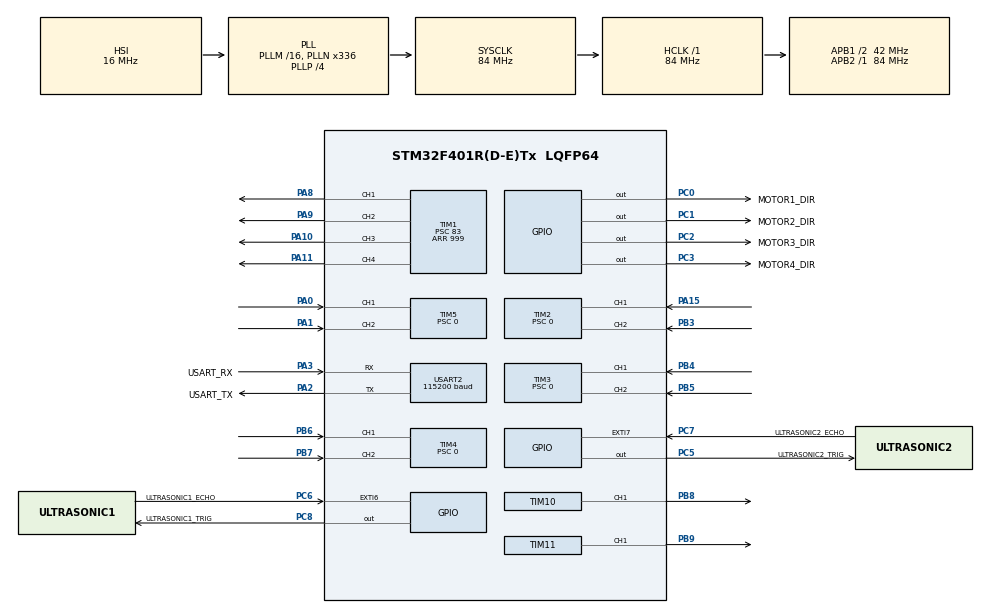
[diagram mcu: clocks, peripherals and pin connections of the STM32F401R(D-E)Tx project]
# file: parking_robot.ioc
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Mcu.Family=STM32F4
Mcu.Name=STM32F401R(D-E)Tx
Mcu.Package=LQFP64
NVIC.EXTI9_5_IRQn=true\:0\:0\:false\:false\:true\:true\:true\:true
NVIC.PriorityGroup=NVIC_PRIORITYGROUP_4
NVIC.USART2_IRQn=true\:0\:0\:false\:false\:true\:true\:true\:true
PA0-WKUP.GPIO_PuPd=GPIO_PULLUP
PA0-WKUP.Signal=S_TIM5_CH1
PA1.GPIO_PuPd=GPIO_PULLUP
PA1.Signal=S_TIM5_CH2
PA10.Signal=S_TIM1_CH3
PA11.Signal=S_TIM1_CH4
PA13.GPIO_Label=TMS
PA13.Mode=Serial_Wire
PA13.Signal=SYS_JTMS-SWDIO
PA14.GPIO_Label=TCK
PA14.Mode=Serial_Wire
PA14.Signal=SYS_JTCK-SWCLK
PA15.GPIO_PuPd=GPIO_PULLUP
PA15.Signal=S_TIM2_CH1_ETR
PA2.GPIO_Label=USART_TX
PA2.GPIO_Mode=GPIO_MODE_AF_PP
PA2.GPIO_PuPd=GPIO_NOPULL
PA2.GPIO_Speed=GPIO_SPEED_FREQ_LOW
PA2.Mode=Asynchronous
PA2.Signal=USART2_TX
PA3.GPIO_Label=USART_RX
PA3.GPIO_Mode=GPIO_MODE_AF_PP
PA3.GPIO_PuPd=GPIO_NOPULL
PA3.GPIO_Speed=GPIO_SPEED_FREQ_LOW
PA3.Mode=Asynchronous
PA3.Signal=USART2_RX
PA8.Signal=S_TIM1_CH1
PA9.Signal=S_TIM1_CH2
PB3.GPIO_PuPd=GPIO_PULLUP
PB3.Signal=S_TIM2_CH2
PB4.GPIO_PuPd=GPIO_PULLUP
PB4.Signal=S_TIM3_CH1
PB5.GPIO_PuPd=GPIO_PULLUP
PB5.Signal=S_TIM3_CH2
PB6.GPIO_PuPd=GPIO_PULLUP
PB6.Signal=S_TIM4_CH1
PB7.GPIO_PuPd=GPIO_PULLUP
PB7.Signal=S_TIM4_CH2
PB8.Signal=S_TIM10_CH1
PB9.Signal=S_TIM11_CH1
PC0.GPIO_Label=MOTOR1_DIR
PC0.GPIO_ModeDefaultOutputPP=GPIO_MODE_OUTPUT_PP
PC0.GPIO_PuPd=GPIO_NOPULL
PC0.GPIO_Speed=GPIO_SPEED_FREQ_LOW
PC0.PinState=GPIO_PIN_RESET
PC0.Signal=GPIO_Output
PC1.GPIO_Label=MOTOR2_DIR
PC1.GPIO_ModeDefaultOutputPP=GPIO_MODE_OUTPUT_PP
PC1.GPIO_PuPd=GPIO_NOPULL
PC1.GPIO_Speed=GPIO_SPEED_FREQ_LOW
PC1.PinState=GPIO_PIN_RESET
PC1.Signal=GPIO_Output
PC2.GPIO_Label=MOTOR3_DIR
PC2.GPIO_ModeDefaultOutputPP=GPIO_MODE_OUTPUT_PP
PC2.GPIO_PuPd=GPIO_NOPULL
PC2.GPIO_Speed=GPIO_SPEED_FREQ_LOW
PC2.PinState=GPIO_PIN_RESET
PC2.Signal=GPIO_Output
PC3.GPIO_Label=MOTOR4_DIR
PC3.GPIO_ModeDefaultOutputPP=GPIO_MODE_OUTPUT_PP
PC3.GPIO_PuPd=GPIO_NOPULL
PC3.GPIO_Speed=GPIO_SPEED_FREQ_LOW
PC3.PinState=GPIO_PIN_RESET
PC3.Signal=GPIO_Output
PC5.GPIO_Label=ULTRASONIC2_TRIG
PC5.GPIO_ModeDefaultOutputPP=GPIO_MODE_OUTPUT_PP
PC5.GPIO_PuPd=GPIO_NOPULL
PC5.GPIO_Speed=GPIO_SPEED_FREQ_LOW
PC5.PinState=GPIO_PIN_RESET
PC5.Signal=GPIO_Output
PC6.GPIO_Label=ULTRASONIC1_ECHO
PC6.GPIO_ModeDefaultEXTI=GPIO_MODE_IT_RISING_FALLING
PC6.GPIO_PuPd=GPIO_NOPULL
PC6.Signal=GPXTI6
PC7.GPIO_Label=ULTRASONIC2_ECHO
PC7.GPIO_ModeDefaultEXTI=GPIO_MODE_IT_RISING_FALLING
PC7.GPIO_PuPd=GPIO_NOPULL
PC7.Signal=GPXTI7
PC8.GPIO_Label=ULTRASONIC1_TRIG
PC8.GPIO_ModeDefaultOutputPP=GPIO_MODE_OUTPUT_PP
PC8.GPIO_PuPd=GPIO_NOPULL
PC8.GPIO_Speed=GPIO_SPEED_FREQ_LOW
PC8.PinState=GPIO_PIN_RESET
PC8.Signal=GPIO_Output
PH0\ -\ OSC_IN.Mode=HSE-External-Clock-Source
PH0\ -\ OSC_IN.Signal=RCC_OSC_IN
PH1\ -\ OSC_OUT.Mode=HSE-External-Clock-Source
PH1\ -\ OSC_OUT.Signal=RCC_OSC_OUT
ProjectManager.HeapSize=0x200
ProjectManager.StackSize=0x400
ProjectManager.TargetToolchain=STM32CubeIDE
RCC.48MHZClocksFreq_Value=48000000
RCC.AHBFreq_Value=84000000
RCC.APB1CLKDivider=RCC_HCLK_DIV2
RCC.APB1Freq_Value=42000000
RCC.APB1TimFreq_Value=84000000
RCC.APB2Freq_Value=84000000
RCC.APB2TimFreq_Value=84000000
RCC.CortexFreq_Value=84000000
RCC.HCLKFreq_Value=84000000
RCC.HSE_VALUE=8000000
RCC.HSI_VALUE=16000000
RCC.LSE_VALUE=32768
RCC.PLLN=336
RCC.PLLP=RCC_PLLP_DIV4
RCC.PLLQ=7
RCC.SYSCLKFreq_VALUE=84000000
RCC.SYSCLKSource=RCC_SYSCLKSOURCE_PLLCLK
RCC.VCOOutputFreq_Value=336000000
SH.S_TIM10_CH1.0=TIM10_CH1,PWM Generation1 CH1
SH.S_TIM11_CH1.0=TIM11_CH1,PWM Generation1 CH1
SH.S_TIM1_CH1.0=TIM1_CH1,PWM Generation1 CH1
SH.S_TIM1_CH2.0=TIM1_CH2,PWM Generation2 CH2
SH.S_TIM1_CH3.0=TIM1_CH3,PWM Generation3 CH3
SH.S_TIM1_CH4.0=TIM1_CH4,PWM Generation4 CH4
SH.S_TIM2_CH1_ETR.0=TIM2_CH1,Encoder_Interface
SH.S_TIM2_CH2.0=TIM2_CH2,Encoder_Interface
SH.S_TIM3_CH1.0=TIM3_CH1,Encoder_Interface
SH.S_TIM3_CH2.0=TIM3_CH2,Encoder_Interface
SH.S_TIM4_CH1.0=TIM4_CH1,Encoder_Interface
SH.S_TIM4_CH2.0=TIM4_CH2,Encoder_Interface
SH.S_TIM5_CH1.0=TIM5_CH1,Encoder_Interface
SH.S_TIM5_CH2.0=TIM5_CH2,Encoder_Interface
TIM1.Channel-PWM\ Generation1\ CH1=TIM_CHANNEL_1
TIM1.Channel-PWM\ Generation2\ CH2=TIM_CHANNEL_2
TIM1.Channel-PWM\ Generation3\ CH3=TIM_CHANNEL_3
TIM1.Channel-PWM\ Generation4\ CH4=TIM_CHANNEL_4
TIM1.Period=999
TIM1.Prescaler=83
TIM10.Channel=TIM_CHANNEL_1
TIM10.Period=19999
TIM10.Prescaler=83
TIM11.Channel=TIM_CHANNEL_1
TIM11.Period=19999
TIM11.Prescaler=83
TIM2.EncoderMode=TIM_ENCODERMODE_TI12
TIM2.IC1Filter=15
TIM2.IC2Filter=15
TIM2.Period=4294967295
TIM2.Prescaler=0
TIM3.EncoderMode=TIM_ENCODERMODE_TI12
TIM3.IC1Filter=15
TIM3.IC2Filter=15
TIM3.Period=65535
TIM3.Prescaler=0
TIM4.EncoderMode=TIM_ENCODERMODE_TI12
TIM4.IC1Filter=15
TIM4.IC2Filter=15
TIM4.Period=65535
TIM4.Prescaler=0
TIM5.EncoderMode=TIM_ENCODERMODE_TI12
TIM5.IC1Filter=15
TIM5.IC2Filter=15
TIM5.Period=4294967295
TIM5.Prescaler=0
TIM9.Period=65535
TIM9.Prescaler=83
USART2.BaudRate=115200
USART2.Parity=PARITY_NONE
USART2.StopBits=STOPBITS_1
USART2.VirtualMode=VM_ASYNC
USART2.WordLength=WORDLENGTH_8B
VP_TIM10_VS_ClockSourceINT.Mode=Enable_Timer
VP_TIM11_VS_ClockSourceINT.Mode=Enable_Timer
VP_TIM1_VS_ClockSourceINT.Mode=Internal
VP_TIM9_VS_ClockSourceINT.Mode=Internal
board=NUCLEO-F401RE

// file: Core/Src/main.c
/* USER CODE BEGIN Header */
/**
  ******************************************************************************
  * @file           : main.c
  * @brief          : Main program body
  ******************************************************************************
  * @attention
  *
  * Copyright (c) 2026 STMicroelectronics.
  * All rights reserved.
  *
  * This software is licensed under terms that can be found in the LICENSE file
  * in the root directory of this software component.
  * If no LICENSE file comes with this software, it is provided AS-IS.
  *
  ******************************************************************************
  */
/* USER CODE END Header */
#include "main.h"

/* USER CODE BEGIN Includes */
#include "parking_robot_firmware.h"
/* USER CODE END Includes */

TIM_HandleTypeDef htim1;
TIM_HandleTypeDef htim2;
TIM_HandleTypeDef htim3;
TIM_HandleTypeDef htim4;
TIM_HandleTypeDef htim5;
TIM_HandleTypeDef htim9;
TIM_HandleTypeDef htim10;
TIM_HandleTypeDef htim11;

UART_HandleTypeDef huart2;

void SystemClock_Config(void);
static void MX_GPIO_Init(void);
static void MX_TIM1_Init(void);
static void MX_TIM2_Init(void);
static void MX_TIM3_Init(void);
static void MX_TIM4_Init(void);
static void MX_TIM5_Init(void);
static void MX_TIM9_Init(void);
static void MX_TIM10_Init(void);
static void MX_TIM11_Init(void);
static void MX_USART2_UART_Init(void);

int main(void)
{

  /* MCU Configuration--------------------------------------------------------*/

  /* Reset of all peripherals, Initializes the Flash interface and the Systick. */
  HAL_Init();

  /* Configure the system clock */
  SystemClock_Config();

  /* Initialize all configured peripherals */
  MX_GPIO_Init();
  MX_TIM1_Init();
  MX_TIM2_Init();
  MX_TIM3_Init();
  MX_TIM4_Init();
  MX_TIM5_Init();
  MX_TIM9_Init();
  MX_TIM10_Init();
  MX_TIM11_Init();
  MX_USART2_UART_Init();
  /* USER CODE BEGIN 2 */
  Robot_Init();
  /* USER CODE END 2 */

  /* Infinite loop */
  while (1)
  {

    /* USER CODE BEGIN 3 */
    Robot_MainLoop();
  }
  /* USER CODE END 3 */
}

void SystemClock_Config(void)
{
  RCC_OscInitTypeDef RCC_OscInitStruct = {0};
  RCC_ClkInitTypeDef RCC_ClkInitStruct = {0};

  /** Configure the main internal regulator output voltage
  */
  __HAL_RCC_PWR_CLK_ENABLE();
  __HAL_PWR_VOLTAGESCALING_CONFIG(PWR_REGULATOR_VOLTAGE_SCALE2);

  /** Initializes the RCC Oscillators according to the specified parameters
  * in the RCC_OscInitTypeDef structure.
  */
  RCC_OscInitStruct.OscillatorType = RCC_OSCILLATORTYPE_HSI;
  RCC_OscInitStruct.HSIState = RCC_HSI_ON;
  RCC_OscInitStruct.HSICalibrationValue = RCC_HSICALIBRATION_DEFAULT;
  RCC_OscInitStruct.PLL.PLLState = RCC_PLL_ON;
  RCC_OscInitStruct.PLL.PLLSource = RCC_PLLSOURCE_HSI;
  RCC_OscInitStruct.PLL.PLLM = 16;
  RCC_OscInitStruct.PLL.PLLN = 336;
  RCC_OscInitStruct.PLL.PLLP = RCC_PLLP_DIV4;
  RCC_OscInitStruct.PLL.PLLQ = 7;
  if (HAL_RCC_OscConfig(&RCC_OscInitStruct) != HAL_OK)
  {
    Error_Handler();
  }

  /** Initializes the CPU, AHB and APB buses clocks
  */
  RCC_ClkInitStruct.ClockType = RCC_CLOCKTYPE_HCLK|RCC_CLOCKTYPE_SYSCLK
                              |RCC_CLOCKTYPE_PCLK1|RCC_CLOCKTYPE_PCLK2;
  RCC_ClkInitStruct.SYSCLKSource = RCC_SYSCLKSOURCE_PLLCLK;
  RCC_ClkInitStruct.AHBCLKDivider = RCC_SYSCLK_DIV1;
  RCC_ClkInitStruct.APB1CLKDivider = RCC_HCLK_DIV2;
  RCC_ClkInitStruct.APB2CLKDivider = RCC_HCLK_DIV1;

  if (HAL_RCC_ClockConfig(&RCC_ClkInitStruct, FLASH_LATENCY_2) != HAL_OK)
  {
    Error_Handler();
  }
}

static void MX_TIM1_Init(void)
{

  TIM_ClockConfigTypeDef sClockSourceConfig = {0};
  TIM_MasterConfigTypeDef sMasterConfig = {0};
  TIM_OC_InitTypeDef sConfigOC = {0};
  TIM_BreakDeadTimeConfigTypeDef sBreakDeadTimeConfig = {0};

  htim1.Instance = TIM1;
  htim1.Init.Prescaler = 83;
  htim1.Init.CounterMode = TIM_COUNTERMODE_UP;
  htim1.Init.Period = 999;
  htim1.Init.ClockDivision = TIM_CLOCKDIVISION_DIV1;
  htim1.Init.RepetitionCounter = 0;
  htim1.Init.AutoReloadPreload = TIM_AUTORELOAD_PRELOAD_DISABLE;
  if (HAL_TIM_Base_Init(&htim1) != HAL_OK)
  {
    Error_Handler();
  }
  sClockSourceConfig.ClockSource = TIM_CLOCKSOURCE_INTERNAL;
  if (HAL_TIM_ConfigClockSource(&htim1, &sClockSourceConfig) != HAL_OK)
  {
    Error_Handler();
  }
  if (HAL_TIM_PWM_Init(&htim1) != HAL_OK)
  {
    Error_Handler();
  }
  sMasterConfig.MasterOutputTrigger = TIM_TRGO_RESET;
  sMasterConfig.MasterSlaveMode = TIM_MASTERSLAVEMODE_DISABLE;
  if (HAL_TIMEx_MasterConfigSynchronization(&htim1, &sMasterConfig) != HAL_OK)
  {
    Error_Handler();
  }
  sConfigOC.OCMode = TIM_OCMODE_PWM1;
  sConfigOC.Pulse = 0;
  sConfigOC.OCPolarity = TIM_OCPOLARITY_HIGH;
  sConfigOC.OCNPolarity = TIM_OCNPOLARITY_HIGH;
  sConfigOC.OCFastMode = TIM_OCFAST_DISABLE;
  sConfigOC.OCIdleState = TIM_OCIDLESTATE_RESET;
  sConfigOC.OCNIdleState = TIM_OCNIDLESTATE_RESET;
  if (HAL_TIM_PWM_ConfigChannel(&htim1, &sConfigOC, TIM_CHANNEL_1) != HAL_OK)
  {
    Error_Handler();
  }
  if (HAL_TIM_PWM_ConfigChannel(&htim1, &sConfigOC, TIM_CHANNEL_2) != HAL_OK)
  {
    Error_Handler();
  }
  if (HAL_TIM_PWM_ConfigChannel(&htim1, &sConfigOC, TIM_CHANNEL_3) != HAL_OK)
  {
    Error_Handler();
  }
  if (HAL_TIM_PWM_ConfigChannel(&htim1, &sConfigOC, TIM_CHANNEL_4) != HAL_OK)
  {
    Error_Handler();
  }
  sBreakDeadTimeConfig.OffStateRunMode = TIM_OSSR_DISABLE;
  sBreakDeadTimeConfig.OffStateIDLEMode = TIM_OSSI_DISABLE;
  sBreakDeadTimeConfig.LockLevel = TIM_LOCKLEVEL_OFF;
  sBreakDeadTimeConfig.DeadTime = 0;
  sBreakDeadTimeConfig.BreakState = TIM_BREAK_DISABLE;
  sBreakDeadTimeConfig.BreakPolarity = TIM_BREAKPOLARITY_HIGH;
  sBreakDeadTimeConfig.AutomaticOutput = TIM_AUTOMATICOUTPUT_DISABLE;
  if (HAL_TIMEx_ConfigBreakDeadTime(&htim1, &sBreakDeadTimeConfig) != HAL_OK)
  {
    Error_Handler();
  }
  HAL_TIM_MspPostInit(&htim1);

}

static void MX_TIM2_Init(void)
{

  TIM_Encoder_InitTypeDef sConfig = {0};
  TIM_MasterConfigTypeDef sMasterConfig = {0};

  htim2.Instance = TIM2;
  htim2.Init.Prescaler = 0;
  htim2.Init.CounterMode = TIM_COUNTERMODE_UP;
  htim2.Init.Period = 4294967295;
  htim2.Init.ClockDivision = TIM_CLOCKDIVISION_DIV1;
  htim2.Init.AutoReloadPreload = TIM_AUTORELOAD_PRELOAD_DISABLE;
  sConfig.EncoderMode = TIM_ENCODERMODE_TI12;
  sConfig.IC1Polarity = TIM_ICPOLARITY_RISING;
  sConfig.IC1Selection = TIM_ICSELECTION_DIRECTTI;
  sConfig.IC1Prescaler = TIM_ICPSC_DIV1;
  sConfig.IC1Filter = 15;
  sConfig.IC2Polarity = TIM_ICPOLARITY_RISING;
  sConfig.IC2Selection = TIM_ICSELECTION_DIRECTTI;
  sConfig.IC2Prescaler = TIM_ICPSC_DIV1;
  sConfig.IC2Filter = 15;
  if (HAL_TIM_Encoder_Init(&htim2, &sConfig) != HAL_OK)
  {
    Error_Handler();
  }
  sMasterConfig.MasterOutputTrigger = TIM_TRGO_RESET;
  sMasterConfig.MasterSlaveMode = TIM_MASTERSLAVEMODE_DISABLE;
  if (HAL_TIMEx_MasterConfigSynchronization(&htim2, &sMasterConfig) != HAL_OK)
  {
    Error_Handler();
  }

}

static void MX_TIM3_Init(void)
{

  TIM_Encoder_InitTypeDef sConfig = {0};
  TIM_MasterConfigTypeDef sMasterConfig = {0};

  htim3.Instance = TIM3;
  htim3.Init.Prescaler = 0;
  htim3.Init.CounterMode = TIM_COUNTERMODE_UP;
  htim3.Init.Period = 65535;
  htim3.Init.ClockDivision = TIM_CLOCKDIVISION_DIV1;
  htim3.Init.AutoReloadPreload = TIM_AUTORELOAD_PRELOAD_DISABLE;
  sConfig.EncoderMode = TIM_ENCODERMODE_TI12;
  sConfig.IC1Polarity = TIM_ICPOLARITY_RISING;
  sConfig.IC1Selection = TIM_ICSELECTION_DIRECTTI;
  sConfig.IC1Prescaler = TIM_ICPSC_DIV1;
  sConfig.IC1Filter = 15;
  sConfig.IC2Polarity = TIM_ICPOLARITY_RISING;
  sConfig.IC2Selection = TIM_ICSELECTION_DIRECTTI;
  sConfig.IC2Prescaler = TIM_ICPSC_DIV1;
  sConfig.IC2Filter = 15;
  if (HAL_TIM_Encoder_Init(&htim3, &sConfig) != HAL_OK)
  {
    Error_Handler();
  }
  sMasterConfig.MasterOutputTrigger = TIM_TRGO_RESET;
  sMasterConfig.MasterSlaveMode = TIM_MASTERSLAVEMODE_DISABLE;
  if (HAL_TIMEx_MasterConfigSynchronization(&htim3, &sMasterConfig) != HAL_OK)
  {
    Error_Handler();
  }

}

static void MX_TIM4_Init(void)
{

  TIM_Encoder_InitTypeDef sConfig = {0};
  TIM_MasterConfigTypeDef sMasterConfig = {0};

  htim4.Instance = TIM4;
  htim4.Init.Prescaler = 0;
  htim4.Init.CounterMode = TIM_COUNTERMODE_UP;
  htim4.Init.Period = 65535;
  htim4.Init.ClockDivision = TIM_CLOCKDIVISION_DIV1;
  htim4.Init.AutoReloadPreload = TIM_AUTORELOAD_PRELOAD_DISABLE;
  sConfig.EncoderMode = TIM_ENCODERMODE_TI12;
  sConfig.IC1Polarity = TIM_ICPOLARITY_RISING;
  sConfig.IC1Selection = TIM_ICSELECTION_DIRECTTI;
  sConfig.IC1Prescaler = TIM_ICPSC_DIV1;
  sConfig.IC1Filter = 15;
  sConfig.IC2Polarity = TIM_ICPOLARITY_RISING;
  sConfig.IC2Selection = TIM_ICSELECTION_DIRECTTI;
  sConfig.IC2Prescaler = TIM_ICPSC_DIV1;
  sConfig.IC2Filter = 15;
  if (HAL_TIM_Encoder_Init(&htim4, &sConfig) != HAL_OK)
  {
    Error_Handler();
  }
  sMasterConfig.MasterOutputTrigger = TIM_TRGO_RESET;
  sMasterConfig.MasterSlaveMode = TIM_MASTERSLAVEMODE_DISABLE;
  if (HAL_TIMEx_MasterConfigSynchronization(&htim4, &sMasterConfig) != HAL_OK)
  {
    Error_Handler();
  }

}

static void MX_TIM5_Init(void)
{

  TIM_Encoder_InitTypeDef sConfig = {0};
  TIM_MasterConfigTypeDef sMasterConfig = {0};

  htim5.Instance = TIM5;
  htim5.Init.Prescaler = 0;
  htim5.Init.CounterMode = TIM_COUNTERMODE_UP;
  htim5.Init.Period = 4294967295;
  htim5.Init.ClockDivision = TIM_CLOCKDIVISION_DIV1;
  htim5.Init.AutoReloadPreload = TIM_AUTORELOAD_PRELOAD_DISABLE;
  sConfig.EncoderMode = TIM_ENCODERMODE_TI12;
  sConfig.IC1Polarity = TIM_ICPOLARITY_RISING;
  sConfig.IC1Selection = TIM_ICSELECTION_DIRECTTI;
  sConfig.IC1Prescaler = TIM_ICPSC_DIV1;
  sConfig.IC1Filter = 15;
  sConfig.IC2Polarity = TIM_ICPOLARITY_RISING;
  sConfig.IC2Selection = TIM_ICSELECTION_DIRECTTI;
  sConfig.IC2Prescaler = TIM_ICPSC_DIV1;
  sConfig.IC2Filter = 15;
  if (HAL_TIM_Encoder_Init(&htim5, &sConfig) != HAL_OK)
  {
    Error_Handler();
  }
  sMasterConfig.MasterOutputTrigger = TIM_TRGO_RESET;
  sMasterConfig.MasterSlaveMode = TIM_MASTERSLAVEMODE_DISABLE;
  if (HAL_TIMEx_MasterConfigSynchronization(&htim5, &sMasterConfig) != HAL_OK)
  {
    Error_Handler();
  }

}

static void MX_TIM9_Init(void)
{

  TIM_ClockConfigTypeDef sClockSourceConfig = {0};

  htim9.Instance = TIM9;
  htim9.Init.Prescaler = 83;
  htim9.Init.CounterMode = TIM_COUNTERMODE_UP;
  htim9.Init.Period = 65535;
  htim9.Init.ClockDivision = TIM_CLOCKDIVISION_DIV1;
  htim9.Init.AutoReloadPreload = TIM_AUTORELOAD_PRELOAD_DISABLE;
  if (HAL_TIM_Base_Init(&htim9) != HAL_OK)
  {
    Error_Handler();
  }
  sClockSourceConfig.ClockSource = TIM_CLOCKSOURCE_INTERNAL;
  if (HAL_TIM_ConfigClockSource(&htim9, &sClockSourceConfig) != HAL_OK)
  {
    Error_Handler();
  }

}

static void MX_TIM10_Init(void)
{

  TIM_OC_InitTypeDef sConfigOC = {0};

  htim10.Instance = TIM10;
  htim10.Init.Prescaler = 83;
  htim10.Init.CounterMode = TIM_COUNTERMODE_UP;
  htim10.Init.Period = 19999;
  htim10.Init.ClockDivision = TIM_CLOCKDIVISION_DIV1;
  htim10.Init.AutoReloadPreload = TIM_AUTORELOAD_PRELOAD_DISABLE;
  if (HAL_TIM_Base_Init(&htim10) != HAL_OK)
  {
    Error_Handler();
  }
  if (HAL_TIM_PWM_Init(&htim10) != HAL_OK)
  {
    Error_Handler();
  }
  sConfigOC.OCMode = TIM_OCMODE_PWM1;
  sConfigOC.Pulse = 0;
  sConfigOC.OCPolarity = TIM_OCPOLARITY_HIGH;
  sConfigOC.OCFastMode = TIM_OCFAST_DISABLE;
  if (HAL_TIM_PWM_ConfigChannel(&htim10, &sConfigOC, TIM_CHANNEL_1) != HAL_OK)
  {
    Error_Handler();
  }
  HAL_TIM_MspPostInit(&htim10);

}

static void MX_TIM11_Init(void)
{

  TIM_OC_InitTypeDef sConfigOC = {0};

  htim11.Instance = TIM11;
  htim11.Init.Prescaler = 83;
  htim11.Init.CounterMode = TIM_COUNTERMODE_UP;
  htim11.Init.Period = 19999;
  htim11.Init.ClockDivision = TIM_CLOCKDIVISION_DIV1;
  htim11.Init.AutoReloadPreload = TIM_AUTORELOAD_PRELOAD_DISABLE;
  if (HAL_TIM_Base_Init(&htim11) != HAL_OK)
  {
    Error_Handler();
  }
  if (HAL_TIM_PWM_Init(&htim11) != HAL_OK)
  {
    Error_Handler();
  }
  sConfigOC.OCMode = TIM_OCMODE_PWM1;
  sConfigOC.Pulse = 0;
  sConfigOC.OCPolarity = TIM_OCPOLARITY_HIGH;
  sConfigOC.OCFastMode = TIM_OCFAST_DISABLE;
  if (HAL_TIM_PWM_ConfigChannel(&htim11, &sConfigOC, TIM_CHANNEL_1) != HAL_OK)
  {
    Error_Handler();
  }
  HAL_TIM_MspPostInit(&htim11);

}

static void MX_USART2_UART_Init(void)
{

  huart2.Instance = USART2;
  huart2.Init.BaudRate = 115200;
  huart2.Init.WordLength = UART_WORDLENGTH_8B;
  huart2.Init.StopBits = UART_STOPBITS_1;
  huart2.Init.Parity = UART_PARITY_NONE;
  huart2.Init.Mode = UART_MODE_TX_RX;
  huart2.Init.HwFlowCtl = UART_HWCONTROL_NONE;
  huart2.Init.OverSampling = UART_OVERSAMPLING_16;
  if (HAL_UART_Init(&huart2) != HAL_OK)
  {
    Error_Handler();
  }

}

static void MX_GPIO_Init(void)
{
  GPIO_InitTypeDef GPIO_InitStruct = {0};

  /* GPIO Ports Clock Enable */
  __HAL_RCC_GPIOH_CLK_ENABLE();
  __HAL_RCC_GPIOC_CLK_ENABLE();
  __HAL_RCC_GPIOA_CLK_ENABLE();
  __HAL_RCC_GPIOB_CLK_ENABLE();

  /*Configure GPIO pin Output Level */
  HAL_GPIO_WritePin(GPIOC, MOTOR1_DIR_Pin|MOTOR2_DIR_Pin|MOTOR3_DIR_Pin|MOTOR4_DIR_Pin
                          |ULTRASONIC2_TRIG_Pin|ULTRASONIC1_TRIG_Pin, GPIO_PIN_RESET);

  /*Configure GPIO pins : MOTOR1_DIR_Pin MOTOR2_DIR_Pin MOTOR3_DIR_Pin MOTOR4_DIR_Pin
                           ULTRASONIC2_TRIG_Pin ULTRASONIC1_TRIG_Pin */
  GPIO_InitStruct.Pin = MOTOR1_DIR_Pin|MOTOR2_DIR_Pin|MOTOR3_DIR_Pin|MOTOR4_DIR_Pin
                          |ULTRASONIC2_TRIG_Pin|ULTRASONIC1_TRIG_Pin;
  GPIO_InitStruct.Mode = GPIO_MODE_OUTPUT_PP;
  GPIO_InitStruct.Pull = GPIO_NOPULL;
  GPIO_InitStruct.Speed = GPIO_SPEED_FREQ_LOW;
  HAL_GPIO_Init(GPIOC, &GPIO_InitStruct);

  /*Configure GPIO pins : ULTRASONIC1_ECHO_Pin ULTRASONIC2_ECHO_Pin */
  GPIO_InitStruct.Pin = ULTRASONIC1_ECHO_Pin|ULTRASONIC2_ECHO_Pin;
  GPIO_InitStruct.Mode = GPIO_MODE_IT_RISING_FALLING;
  GPIO_InitStruct.Pull = GPIO_NOPULL;
  HAL_GPIO_Init(GPIOC, &GPIO_InitStruct);

  /* EXTI interrupt init*/
  HAL_NVIC_SetPriority(EXTI9_5_IRQn, 0, 0);
  HAL_NVIC_EnableIRQ(EXTI9_5_IRQn);

}

void Error_Handler(void)
{
  __disable_irq();
  while (1)
  {
  }
}
